# DDR0_CTLPHY_WRAP_PHY_CFG register map
Vendor: Texas Instruments
Registers are 32-bit, access per field, reset 0x0 unless marked. A register's access mark holds for its fields unless they carry their own. Offsets are as the file gives them; [hi:lo] are bit positions; lines under a group give offsets from that group; {n}, {i} and the like mark numbered series.

## DDR0_CTLPHY_WRAP_PHY_CFG (part 2 of 4)
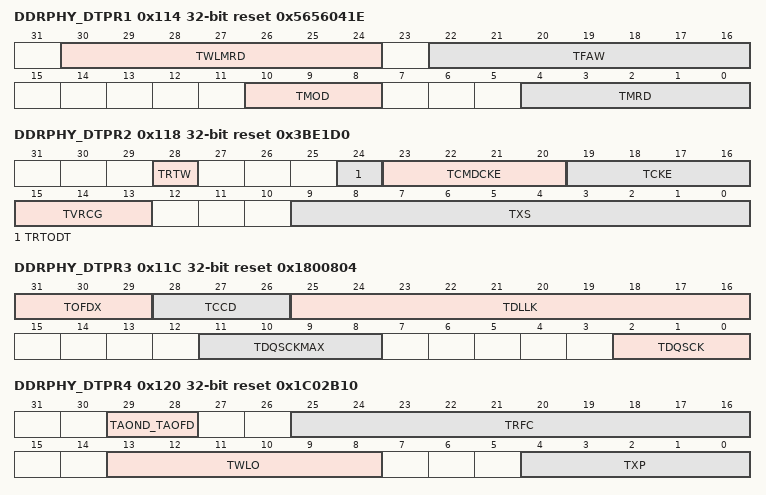
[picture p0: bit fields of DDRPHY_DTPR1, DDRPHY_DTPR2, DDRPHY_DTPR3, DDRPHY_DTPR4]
0x114 DDRPHY_DTPR1 reset 0x5656041E — DRAM Timing Parameters Register 1
  [30:24] TWLMRD rw — Minimum delay from when write leveling mode is programmed to the first DQS/DQS# rising edge. Larger values give more conservative command-to-command timings.
  [22:16] TFAW rw — 4-bank activate period. No more than 4-bank activate commands may be issued in a given tFAW period. Only applies to 8-bank devices. Valid values are 2 to 127. Larger values give more conservative command-to-command timings.
  [10:8] TMOD rw — Load mode update delay (DDR4 and DDR3 only). The minimum time between a load mode register command and a non-load mode register command. Valid values for DDR4 are:
  [4:0] TMRD rw — Load mode cycle time: The minimum time between a load mode register command and any other command. For DDR3 this is the minimum time between two load mode register commands. An offset is applied in some DRAM modes to extend the range of the register as follows:
0x118 DDRPHY_DTPR2 reset 0x3BE1D0 — DRAM Timing Parameters Register 2
  [28] TRTW rw — Read to Write command delay. Valid values are:
  [24] TRTODT rw — Read to ODT delay. Setting to 1 increases read-to-write transaction spacing by 1 DRAM clock cycle. This is intended a programmable margin for host ODT turn-off timing.
  [23:20] TCMDCKE rw — LPDDR4 mode only. tCMDCKE - Delay from Valid command to CKE Input low. Also used for tESCKE - Delay from SRE command to CKE Input low
  [19:16] TCKE rw — CKE minimum pulse width. Also specifies the minimum time that the SDRAM must remain in power down or self refresh mode. For DDR3 and LPDDR3, this parameter must be set to the value of tCKESR which is usually bigger than the value of tCKE. Valid values are 2 to 15. Larger values give more conservative command-to-command timings.
  [15:13] TVRCG rw — tVRCG_ENABLE/VRCG_DISABLE - VREF high current mode enable/Disable time for MR13 MRW during DRAM initialization in LPDDR4 mode. Number of DRAM clocks required to meet tVRCG_ENABLE/VRCG_DISABLE timing. Valid values are:
  [9:0] TXS rw — Self refresh exit delay. The minimum time between a self refresh exit command and any other command. This parameter must be set to the maximum of the various minimum self refresh exit delay parameters specified in the SDRAM datasheet, i.e. max(tXS, tXSDLL) for DDR3 and DDR4. Valid values are 2 to 1023. For LPDDR3 and LPDDR4 mode, program this value to set tXSR as specified in the SDRAM datasheet. Larger values give more conservative command-to-command timings.
0x11C DDRPHY_DTPR3 reset 0x1800804 — DRAM Timing Parameters Register 3
  [31:29] TOFDX rw — ODT turn-off delay extension. The delays are in clock cycles. Valid values are:
  [28:26] TCCD rw — Read to read and write to write command delay. In DDR4 mode, this field is ignored and MR6.tCCDL is used instead. Valid values are:
  [25:16] TDLLK rw — DLL locking time. The PUB adds an offset of 128 to this programmed register value to derive the final tDLLK value. Valid values are 0 to 1023, giving valid tDLLK values of 128 to 1151. Default value gives tDLLK value of 512.
  [11:8] TDQSCKMAX rw — Maximum DQS output access time from CK/CK# (LPDDR3/4 only). This value is used for implementing read-to-write spacing. Valid values are 1 to 8. Programming larger values increase read-to-write timing margins; smaller value optimize read-to-write scheduling (provided protocol requirements are still met).
  [2:0] TDQSCK rw — DQS output access time from CK/CK# (LPDDR3/4 only). This value is used for computing the read latency. Valid values are 1 to 8.
0x120 DDRPHY_DTPR4 reset 0x1C02B10 — DRAM Timing Parameters Register 4
  [29:28] TAOND_TAOFD rw — ODT turn-on/turn-off delays. The delays are in clock cycles. Valid values are:
  [25:16] TRFC rw — Refresh-to-Refresh: Indicates the minimum time, in clock cycles, between two refresh commands or between a refresh and an active command. This is derived from the minimum refresh interval from the datasheet, tRFC(min), divided by the clock cycle time. The default number of clock cycles is for the largest JEDEC tRFC(min parameter value supported. Larger values give more conservative command-to-command timings.
  [13:8] TWLO rw — Write leveling output delay: Number of clock cycles from when write leveling DQS is driven high by the control block to when the results from the SDRAM on DQ is sampled by the control block. This must include the SDRAM tWLO timing parameter plus the round trip delay from control block to SDRAM back to control block. Larger values give more conservative command-to-command timings.
  [4:0] TXP rw — Power down exit delay
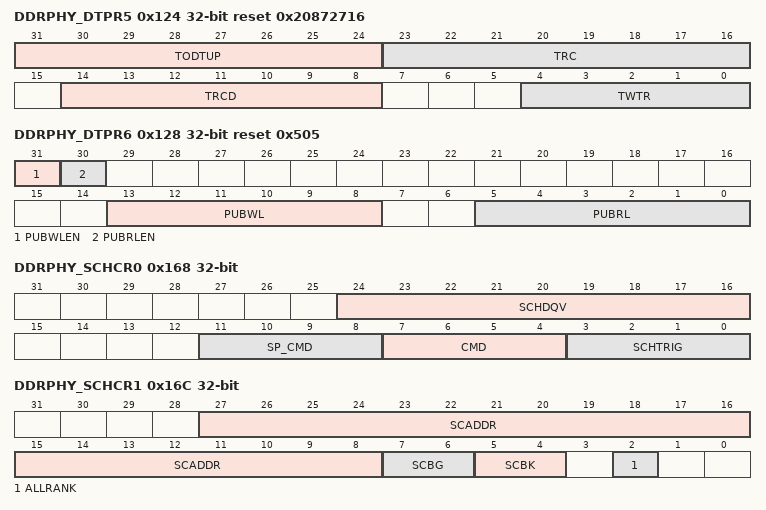
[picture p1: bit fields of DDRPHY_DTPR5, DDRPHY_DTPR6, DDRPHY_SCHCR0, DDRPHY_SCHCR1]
0x124 DDRPHY_DTPR5 reset 0x20872716 — DRAM Timing Parameters Register 5
  [31:24] TODTUP rw — LPDDR4 CA ODT value update time in DRAM clocks. This timing parameter is used during MRW to MR11 during PUB DRAM initialization. The default value of 32 DRAM clocks is to meet timing requirement of 20ns at 3200Mbps speed. Larger values give more conservative command-to-command timings.
  [23:16] TRC rw — Activate to activate command delay (same bank).
  [14:8] TRCD rw — Activate to read or write delay. Minimum time from when an activate command is issued to when a read or write to the activated row can be issued. In LPDDR3 mode, use tRCD(slow) - max(24ns,3nCK) to set this parameter. Also PUB adds an offset of 8 to the register value. In DDR3, DDR4, and LPDDR4 modes, no offset is added. Larger values give more conservative command-to-command timings.
  [4:0] TWTR rw — DRAM Internal write to read command delay. For DDR4, use tWTR_L (write-to-read delay for same bank group). Larger values give more conservative command-to-command timings.
0x128 DDRPHY_DTPR6 reset 0x505 — DRAM Timing Parameters Register 6
  [31] PUBWLEN rw — PUB Write Latency Enable: Specifies, if set, that the PUB should use the write latency specified in DDRPHY_DTPR6[PUBWL]. Otherwise, if not set, the PUB write latency is automatically calculated from the mode register settings.
  [30] PUBRLEN rw — PUB Read Latency Enable: Specifies, if set, that the PUB should use the read latency specified in DDRPHY_DTPR6[PUBRL]. Otherwise, if not set, the PUB read latency is automatically calculated from the mode register settings.
  [13:8] PUBWL rw — Write Latency: Specifies the write latency that should be used inside the PUB when DDRPHY_DTPR6[PUBWL] is set to 1. Valid values are 1 to 31. If PUBWLEN is not set, then the PUB write latency is automatically calculated from the mode register settings.
  [5:0] PUBRL rw — Read Latency: Specifies the read latency that should be used inside the PUB when DDRPHY_DTPR6[PUBRLEN] is set to 1. Valid values are 1 to 31. If PUBRL is not set, then the PUB read latency is automatically calculated from the mode register settings.
0x168 DDRPHY_SCHCR0 access not given — Scheduler Command Register 0
  [24:16] SCHDQV rw — Scheduler Command DQ Value. Specifies the value to be driven on the DQ bus during a mode register set command in per-DRAM addressability mode (DDR4 only). Each bit specifies a value to be driven on all DQ bits for a lane. Bit [0] is for the DQ bits on lane 0, bit [1] is for the DQ bits on lane 1, etc.
  [11:8] SP_CMD rw — Special Command codes: Only applicable when CMD field is set to SPECIAL_COMMAND(4’b0111) Valid values are:
  [7:4] CMD rw — Specifies the Command to be issued. Valid values are:
  [3:0] SCHTRIG — Mode Register Command Trigger: Initialization Trigger: A write of ‘1’ to this bit triggers the mode register command FSM to issue commands specified in bits [11:2] of this register. A bit setting of 1 means the step will be executed as part of the sequence, while a setting of ‘0’ means the step will be bypassed. The Mod Register Set trigger bit is self-clearing. (access RW1C)
0x16C DDRPHY_SCHCR1 — Scheduler Command Register 1
  [27:8] SCADDR rw — Scheduler Command Address Specifies the value to be driven on the address bus.
  [7:6] SCBG rw — Scheduler Command Bank Group: Specifies the value to be driven on BG[1:0] .
  [5:4] SCBK rw — Scheduler Command Bank Address: Specifies the value to be driven on BA[1:0] .
  [2] ALLRANK rw — All Ranks enabled: When set the commands issued by the mode register command FSM are set to all ranks.
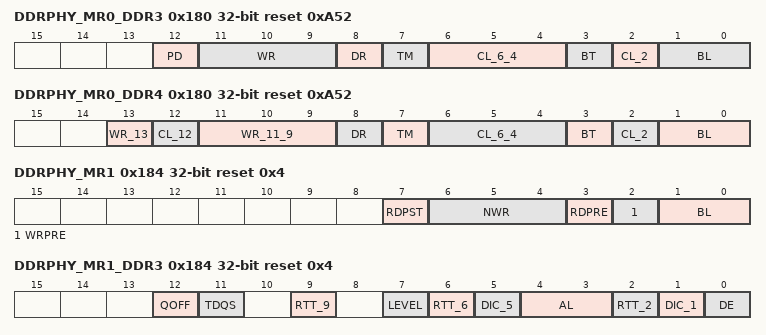
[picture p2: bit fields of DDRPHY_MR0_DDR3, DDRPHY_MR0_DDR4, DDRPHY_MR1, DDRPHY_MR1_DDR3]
0x180 DDRPHY_MR0_DDR3 reset 0xA52 — DDR3 Mode Register 0
  [12] PD rw — Power-Down Control: Controls the exit time for power-down modes. Refer to SDRAM datasheet for details on power-down modes. Valid values are:
  [11:9] WR rw — Write Recovery: This is the value of the write recovery in clock cycles. It is calculated by dividing the datasheet write recovery time, tWR (ns) by the datasheet clock cycle time, tCK (ns) and rounding up a non-integer value to the next integer. Valid values are:
  [8] DR rw — DLL Reset: Writing a 1b1 to this bit will reset the SDRAM DLL. The recommendation is to program this bit to 1b0 at all times.
  [7] TM rw — Operating Mode: Selects either normal operating mode (0) or test mode (1). Test mode is RESERVED for the manufacturer and should not be used.
  [6:4] CL_6_4 rw — CAS Latency: The delay, in clock cycles, between when the SDRAM registers receive a read command to when data is available. Valid values are:
  [3] BT rw — Burst Type: Indicates whether a burst is sequential (0) or interleaved (1).
  [2] CL_2 rw — CAS Latency: The delay, in clock cycles, between when the SDRAM registers receive a read command to when data is available. Valid values are:
  [1:0] BL rw — Burst Length: Determines the maximum number of column locations that can be accessed during a given read or write command. Valid values are:
0x180 DDRPHY_MR0_DDR4 reset 0xA52 — DDR4 Mode Register 0
  [13] WR_13 rw — Write Recovery and Read to Precharge
  [12] CL_12 rw — CAS Latency: The delay, in clock cycles, between when the SDRAM registers a read command to when data is available. Valid values are:
  [11:9] WR_11_9 rw — Write Recovery and Read to Precharge: Write Recovery and Read to Precharge. Valid values are:
  [8] DR rw — DLL Reset: Writing a 1b1 to this bit will reset the SDRAM DLL. The recommendation is to program this bit to 1b0 at all times.
  [7] TM rw — Operating Mode: Selects either normal operating mode (0) or test mode (1). Test mode is RESERVED for the manufacturer and should not be used.
  [6:4] CL_6_4 rw — CAS Latency: The delay, in clock cycles, between when the SDRAM registers receive a read command to when data is available. Valid values are:
  [3] BT rw — Burst Type: Indicates whether a burst is sequential (0) or interleaved (1).
  [2] CL_2 rw — CAS Latency: The delay, in clock cycles, between when the SDRAM registers receive a read command to when data is available. Valid values are:
  [1:0] BL rw — Burst Length: Determines the maximum number of column locations that can be accessed during a given read or write command. Valid values are:
0x184 DDRPHY_MR1 reset 0x4 — LPDDR4 Mode Register 1
  [7] RDPST rw — Read Postamble Length
  [6:4] NWR rw — Write-recovery for auto-precharge command
  [3] RDPRE rw — Read Preamble Type
  [2] WRPRE rw — Write Preamble length
  [1:0] BL rw — Burst length:
0x184 DDRPHY_MR1_DDR3 reset 0x4 — DDR3 Mode Register 1
  [12] QOFF rw — Output Enable/Disable: When 1b0, all outputs function normal; when 1b1 all SDRAM outputs are disabled removing output buffer current. This feature is intended to be used for IDD characterization of read current and should not be used in normal operation.
  [11] TDQS rw — Termination Data Strobe: When enabled (1b1) TDQS provides additional termination resistance outputs that may be useful in some system configurations. Refer to the SDRAM datasheet for details.
  [9] RTT_9 rw — On Die Termination: Selects the effective resistance for SDRAM on die termination. Valid values are:
  [7] LEVEL rw — Write Leveling Enable: Enables write-leveling when set.
  [6] RTT_6 rw — On Die Termination: Selects the effective resistance for SDRAM on die termination. Valid values are:
  [5] DIC_5 rw — Output Driver Impedance Control: Controls the output drive strength. Valid values are:
  [4:3] AL rw — Posted CAS Additive Latency: Setting additive latency that allows read and write commands to be issued to the SDRAM earlier than normal (refer to SDRAM datasheet for details). Valid values are:
  [2] RTT_2 rw — On Die Termination: Selects the effective resistance for SDRAM on die termination. Valid values are:
  [1] DIC_1 rw — Output Driver Impedance Control: Controls the output drive strength. Valid values are:
  [0] DE rw — DLL Enable/Disable
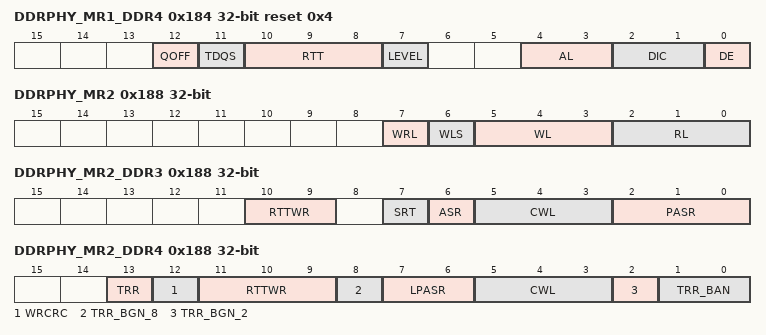
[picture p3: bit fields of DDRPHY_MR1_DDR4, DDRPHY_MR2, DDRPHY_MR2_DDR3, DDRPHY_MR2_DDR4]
0x184 DDRPHY_MR1_DDR4 reset 0x4 — DDR4 Mode Register 1
  [12] QOFF rw — Output Enable/Disable: When ‘0’, all outputs function normal; when ‘1’ all SDRAM outputs are disabled removing output buffer current. This feature is intended to be used for IDD characterization of read current and should not be used in normal operation.
  [11] TDQS rw — Termination Data Strobe: When enabled (‘1’) TDQS provides additional termination resistance outputs that may be useful in some system configurations. Refer to the SDRAM datasheet for details.
  [10:8] RTT rw — On Die Termination: Selects the effective resistance for SDRAM on die termination. Valid values are:
  [7] LEVEL rw — Write Leveling Enable: Enables write-leveling when set.
  [4:3] AL rw — Posted CAS Additive Latency: Setting additive latency that allows read and write commands to be issued to the SDRAM earlier than normal (refer to SDRAM datasheet for details). Valid values are:
  [2:1] DIC rw — Output Driver Impedance Control: Controls the output drive strength. Valid values are:
  [0] DE rw — DLL Enable/Disable
0x188 DDRPHY_MR2 — LPDDR4 Mode Register 2
  [7] WRL rw — Write Leveling
  [6] WLS rw — Write Latency Set
  [5:3] WL rw — WL Set A (MR2 OP[6] = 0b)
  [2:0] RL rw — RL and nRTP for DBI-RD Disabled (MR3 OP[6] =0b)
0x188 DDRPHY_MR2_DDR3 — DDR3 Mode Register 2
  [10:9] RTTWR rw — Dynamic ODT: Selects RTT for dynamic ODT. Valid values are:
  [7] SRT rw — Self-Refresh Temperature Range: Selects either normal (‘0’) or extended (‘1’) operating temperature range during self-refresh.
  [6] ASR rw — Auto Self-Refresh: When enabled (‘1’), SDRAM automatically provides self-refresh power management functions for all supported operating temperature values. Otherwise the SRT bit must be programmed to indicate the temperature range.
  [5:3] CWL rw — CAS Write Latency: The delay, in clock cycles, between when the SDRAM registers receive a write command to when write data is available. Valid values are:
  [2:0] PASR rw — Partial Array Self Refresh: Specifies that data located in areas of the array beyond the specified location will be lost if self refresh is entered. Valid settings for 4 banks are:
0x188 DDRPHY_MR2_DDR4 — DDR4 Mode Register 2
  [13] TRR rw — TRR Mode setting:
  [12] WRCRC rw — Write CRC. When ‘`1’, CRC is enabled for write operation.
  [11:9] RTTWR rw — Dynamic ODT: Selects RTT for dynamic ODT. Valid values are:
  [8] TRR_BGN_8 rw — Defines the bank group (BGn) to which TRR will be applied
  [7:6] LPASR rw — Low Power Array Self Refresh (LP ASR). Valid values are:
  [5:3] CWL rw — CAS Write Latency: The delay, in clock cycles, between when the SDRAM registers a write command to when write data is available. Valid values are:
  [2] TRR_BGN_2 rw — Defines the bank group (BGn) to which TRR will be applied
  [1:0] TRR_BAN rw — Defines which bank (BAn) the target row is located.
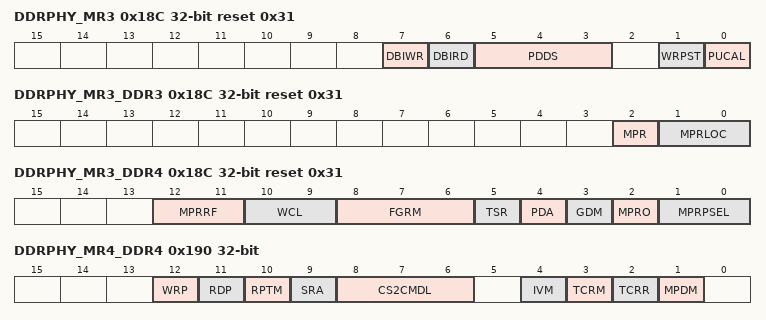
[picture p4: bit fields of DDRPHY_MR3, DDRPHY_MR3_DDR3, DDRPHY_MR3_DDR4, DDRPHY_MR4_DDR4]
0x18C DDRPHY_MR3 reset 0x31 — LPDDR4 Mode Register 3
  [7] DBIWR rw — DBI-write enable
  [6] DBIRD rw — DBI-read enable
  [5:3] PDDS rw — Pull-down drive strength
  [1] WRPST rw — Write Post-amble Length
  [0] PUCAL rw — Pull-up calibration point
0x18C DDRPHY_MR3_DDR3 reset 0x31 — DDR3 Mode Register 3
  [2] MPR rw — Multi-Purpose Register Enable: Enables, if set, that read data should come from the Multi-Purpose Register. Otherwise read data come from the DRAM array.
  [1:0] MPRLOC rw — Multi-Purpose Register (MPR) Location: Selects MPR data location: Valid value are:
0x18C DDRPHY_MR3_DDR4 reset 0x31 — DDR4 Mode Register 3
  [12:11] MPRRF rw — Multi-Purpose Register Read Format Valid values are:
  [10:9] WCL rw — Write Command Latency when CRC and DM are enabled. Valid values are:
  [8:6] FGRM rw — Fine Granularity Refresh Mode. Valid values are:
  [5] TSR rw — Temp sensor readout
  [4] PDA rw — Per DRAM Addressability: Enables, when set, per DRAM addressability to select a device on a rank.
  [3] GDM rw — Geardown Mode: Specifies the internal clocking rate used for geardown mode:
  [2] MPRO rw — Multi-Purpose Operation: Enables, if set, normal MPR operation. Otherwise MPR operation is to write or read data to/from the MPR.
  [1:0] MPRPSEL rw — Multi-Purpose Register (MPR) Page Selection: Selects MPR data location: Valid value are:
{0x180+4i} DDRPHY_MR{i} (i=4..7) — LPDDR4 Mode Register {i}
0x190 DDRPHY_MR4_DDR3 — DDR3 Mode Register 4
0x190 DDRPHY_MR4_DDR4 — DDR4 Mode Register 4
  [12] WRP rw — Write Preamble. Valid values are:
  [11] RDP rw — Read Preamble
  [10] RPTM rw — Read Preamble Training Mode
  [9] SRA rw — Self Refresh Abord
  [8:6] CS2CMDL rw — CS to Command Latency Mode Valid values are:
  [4] IVM rw — Internal Vref Monitor:
  [3] TCRM rw — Temperature Controlled Refresh Mode
  [2] TCRR rw — Temperature Controlled Refresh Range
  [1] MPDM rw — Maximum Power Down Mode
0x194 DDRPHY_MR5_DDR3 reset 0x400 — DDR3 Mode Register 5
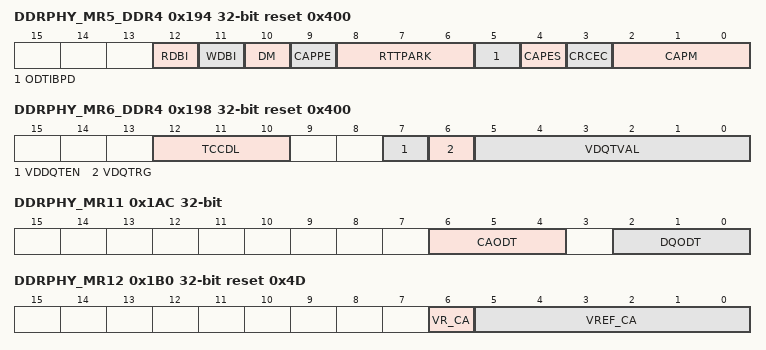
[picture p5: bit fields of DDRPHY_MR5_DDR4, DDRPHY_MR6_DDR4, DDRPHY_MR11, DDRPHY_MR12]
0x194 DDRPHY_MR5_DDR4 reset 0x400 — DDR4 Mode Register 5
  [12] RDBI rw — Read DBI
  [11] WDBI rw — Write DBI
  [10] DM rw — Data Mask
  [9] CAPPE rw — CA parity Persistent Error
  [8:6] RTTPARK rw — RTT_PARK Valid values are:
  [5] ODTIBPD rw — ODT Input Buffer during Power Down mode
  [4] CAPES rw — C/A Parity Error Status
  [3] CRCEC rw — CRC Error Clear
  [2:0] CAPM rw — C/A Parity Latency Mode Valid values are:
0x198 DDRPHY_MR6_DDR3 reset 0x400 — DDR3 Mode Register 6
0x198 DDRPHY_MR6_DDR4 reset 0x400 — DDR4 Mode Register 6
  [12:10] TCCDL rw — CAS_n to CAS_n command delay for same bank group (tCCD_L). Valid values are:
  [7] VDDQTEN rw — VrefDQ Training Enable
  [6] VDQTRG rw — VrefDQ Training Range
  [5:0] VDQTVAL rw — VrefDQ Training Values Refer to the JEDEC spec for more information
0x19C DDRPHY_MR7_DDR3 — LPDDR2 Mode Register 7
0x19C DDRPHY_MR7_DDR4 — DDR4 Mode Register 7
  [15:0] RSVD_15_0 rw — Reserve for future use.
0x1AC DDRPHY_MR11 — LPDDR4 Mode Register 11
  [6:4] CAODT rw, [2:0] DQODT rw
0x1AC DDRPHY_MR11_DDR3 — DDR3 Mode Register 11
0x1AC DDRPHY_MR11_DDR4 — DDR4 Mode Register 11
0x1B0 DDRPHY_MR12 reset 0x4D — LPDDR4 Mode Register 12
  [6] VR_CA rw — VREF DQ Range select 0b: Range[0] enabled 1b: Range[1] enabled
  [5:0] VREF_CA rw — Controls the VREF(ca) levels for Frequency-Set-Point[1:0]. Values from either VR(ca)[0] or VR(ca)[1] may be selected by setting VR-CA appropriately.
0x1B0 DDRPHY_MR12_DDR3 reset 0x4D — DDR3 Mode Register 12
0x1B0 DDRPHY_MR12_DDR4 reset 0x4D — DDR4 Mode Register 12
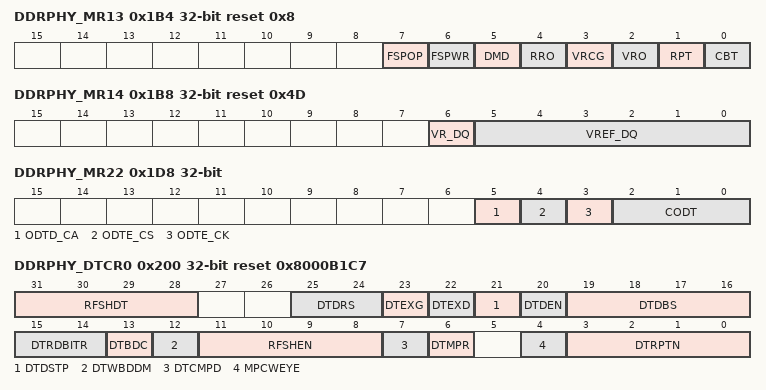
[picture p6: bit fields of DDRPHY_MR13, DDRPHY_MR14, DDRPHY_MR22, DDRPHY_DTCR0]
0x1B4 DDRPHY_MR13 reset 0x8 — LPDDR4 Mode Register 13
  [7] FSPOP rw — Frequency Set Point Operation mode
  [6] FSPWR rw — Frequency Set Point Write enable
  [5] DMD rw — Data mask disable:
  [4] RRO rw — Refresh Rate Option
  [3] VRCG rw — Vref current generator:
  [2] VRO rw — Vref Output:
  [1] RPT rw — Read Preamble Training Mode
  [0] CBT rw — Command Bus Training:
0x1B4 DDRPHY_MR13_DDR3 reset 0x8 — DDR3 Mode Register 13
0x1B4 DDRPHY_MR13_DDR4 reset 0x8 — DDR4 Mode Register 13
0x1B8 DDRPHY_MR14 reset 0x4D — LPDDR4 Mode Register 14
  [6] VR_DQ rw — VREF DQ Range select 0b: Range[0] enabled 1b: Range[1] enabled
  [5:0] VREF_DQ rw — Controls the VREF(dq) levels for Frequency-Set-Point[1:0]. Values from either VR(dq)[0] or VR(dq)[1] may be selected by setting VR_DQ appropriately.
0x1B8 DDRPHY_MR14_DDR3 reset 0x4D — DDR3 Mode Register 14
0x1B8 DDRPHY_MR14_DDR4 reset 0x4D — DDR4 Mode Register 14
0x1D8 DDRPHY_MR22 — LPDDR4 Mode Register 22
  [5] ODTD_CA rw — CA ODT termination disable
  [4] ODTE_CS rw — ODT CS override
  [3] ODTE_CK rw — ODT CK override
  [2:0] CODT rw — Host ODT value for DRAM Voh calibration
0x1D8 DDRPHY_MR22_DDR3 — DDR3 Mode Register 22
0x1D8 DDRPHY_MR22_DDR4 — DDR4 Mode Register 22
0x200 DDRPHY_DTCR0 access not given reset 0x8000B1C7 — Data Training Configuration Register 0
  [31:28] RFSHDT rw — Refresh During Training: A non-zero value specifies that a burst of refreshes equal to the number specified in this field inserted during training. Refer to the registers DDRPHY_PGCR2[TREFPRD] to define the refresh period. Programming with value of 0 in this register field will not insert any Refresh during training.
  [25:24] DTDRS rw — Data Training Debug Rank Select: Selects the rank during training debug mode.
  [23] DTEXG rw — Data Training with Early/Extended Gate: Specifies if set that the DQS gate training should be performed with an early/extended gate as specified in DDRPHY_DX8SLnDQSCTL[DQSGX]. DTEXG=1 is not supported.
  [22] DTEXD rw — Data Training Extended Write DQS: Enables, if set, an extended write DQS whereby two additional pulses of DQS are added as post-amble to a burst of writes. Generally this should only be enabled when running read bit deskew with the intention of performing read eye deskew prior to running write leveling adjustment.
  [21] DTDSTP — Data Training Debug Step: A write of ‘1’ to this bit steps the data training algorithm through a single step. This bit is self clearing. (access RW1C)
  [20] DTDEN rw — Data Training Debug Enable: Enables, if set, the data training to run in a single-step debug mode. In this mode, DTDSTP must be repeatedly asserted to step through the data training.
  [19:16] DTDBS rw — Data Training Debug Byte Select: Selects the byte during data training debug mode.
  [15:14] DTRDBITR rw — Data Training read DBI deskewing configuration. Configures the data training read bit deskewing algorithm optional RDBI deskew functionality. Valid values are:
  [13] DTBDC rw — Data Training Bit Deskew Centering: Enables, if set, eye centering capability during write and read bit deskew training.
  [12] DTWBDDM rw — Data Training Write Bit Deskew Data Mask. If set it enables write bit deskew of the data mask.
  [11:8] RFSHEN rw — Refreshes Issued During Entry to Training:
  [7] DTCMPD rw — Data Training Compare Data: Specifies, if set, that DQS gate training should also check if the returning read data is correct. Otherwise data-training only checks if the correct number of DQS edges were returned.
  [6] DTMPR rw — Data Training Using MPR: Specifies, if set, that DQS gate training should use the SDRAM Multi-Purpose Register (MPR) register. Otherwise data-training is performed by first writing to some locations in the SDRAM and then reading them back.
  [4] MPCWEYE rw — WEYE Training using MPC FIFO Commands: This is applicable in LPDDR4 mode. When this bit is set to 1, WEYE training will be performed with MPC FIFO commands instead of normal Writes/Reads
  [3:0] DTRPTN rw — Data Training Repeat Number: Repeat number used to confirm stability of DDR write or read. The valid values are 1 to 15.
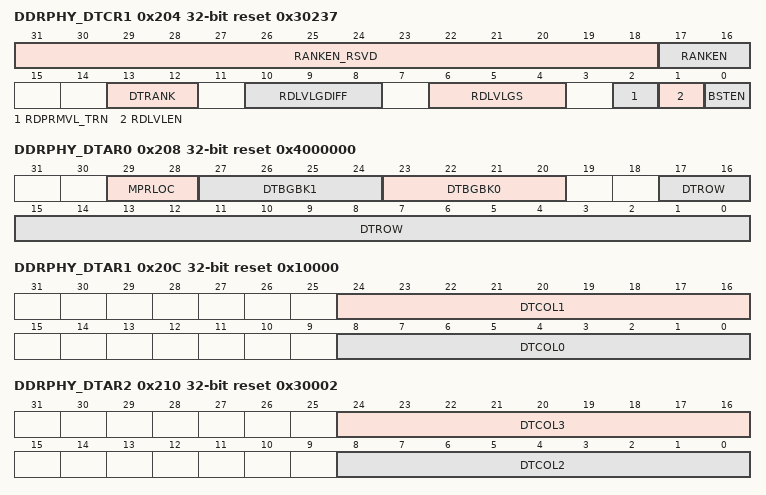
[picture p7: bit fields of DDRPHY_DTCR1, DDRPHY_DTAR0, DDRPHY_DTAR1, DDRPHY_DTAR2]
0x204 DDRPHY_DTCR1 reset 0x30237 — Data Training Configuration Register 1
  [31:18] RANKEN_RSVD ro — Reserved
  [17:16] RANKEN rw — Rank Enable.
  [13:12] DTRANK rw — Data Training Rank: Selects the SDRAM rank to be used during data bit deskew.
  [10:8] RDLVLGDIFF rw — Read Leveling Gate Sampling Difference: width of DQS sampling window. Encoded as a fraction of the DDR clock period follows:
  [6:4] RDLVLGS rw — Read Leveling Gate Shift: delay reduction to apply to gate after it has been aligned to DQS. Encoded as a fraction of the DDR clock period follows:
  [2] RDPRMVL_TRN rw — Read Preamble Training enable: engages read preamble training mode in DDR4 DRAM during gate training
  [1] RDLVLEN rw — Read Leveling Enable: Run a DQS sampling scheme using the gate to align the rising edges of DQS and the gate after which a delay reduction is applied to the gate (see RDLVLGS).
  [0] BSTEN rw — Basic Gate Training Enable: Runs a trial and error algorithm to progressively evaluate gate positions and narrow down to a working one
0x208 DDRPHY_DTAR0 reset 0x4000000 — Data Training Address Register 0
  [29:28] MPRLOC rw — Multi-Purpose Register (MPR) Location: Selects MPR data location to use as a training pattern during gate training. Valid values are:
  [27:24] DTBGBK1 rw — Data Training Bank Group and Bank Address: Selects the SDRAM bank group and bank address to be used during data training in DDR4 and LPDDR4 modes only. When in DDR4 mode, DTBGBK1[27:27] specifies the bank group and DTBGBK1[25:24] specifies the bank address. When not in DDR4 mode, DTBGBK1 is not applicable.
  [23:20] DTBGBK0 rw — Data Training Bank Group and Bank Address: Selects the SDRAM bank group and bank address to be used during data training. When in DDR4 mode, DTBGBK0[23:22] specifies the bank group and DTBGBK0[21:20] specifies the bank address. When not in DDR4 or LPDDR4 modes DTBGBK0[22:20] specify the bank address.
  [17:0] DTROW rw — Data Training Row Address: Selects the SDRAM row address to be used during data training.
0x20C DDRPHY_DTAR1 reset 0x10000 — Data Training Address Register 1
  [24:16] DTCOL1 rw — Data Training Column Address: Selects the SDRAM column address to be used during data training. Specified in multiples of 8 such that the address used is {DTCOL1,3’b000}. For LPDDR4, specified in multiples of 16 such that the address used is (DTCOLn,4'b0000).
  [8:0] DTCOL0 rw — Data Training Column Address: Selects the SDRAM column address to be used during data training. Specified in multiples of 8 such that the address used is {DTCOL0,3’b000}. For LPDDR4, specified in multiples of 16 such that the address used is (DTCOLn,4'b0000).
0x210 DDRPHY_DTAR2 reset 0x30002 — Data Training Address Register 2
  [24:16] DTCOL3 rw — Data Training Column Address: Selects the SDRAM column address to be used during data training. Specified in multiples of 8 such that the address used is {DTCOL3,3’b000}. For LPDDR4, specified in multiples of 16 such that the address used is (DTCOLn,4'b0000).
  [8:0] DTCOL2 rw — Data Training Column Address: Selects the SDRAM column address to be used during data training. Specified in multiples of 8 such that the address used is {DTCOL2,3’b000}. For LPDDR4, specified in multiples of 16 such that the address used is (DTCOLn,4'b0000).
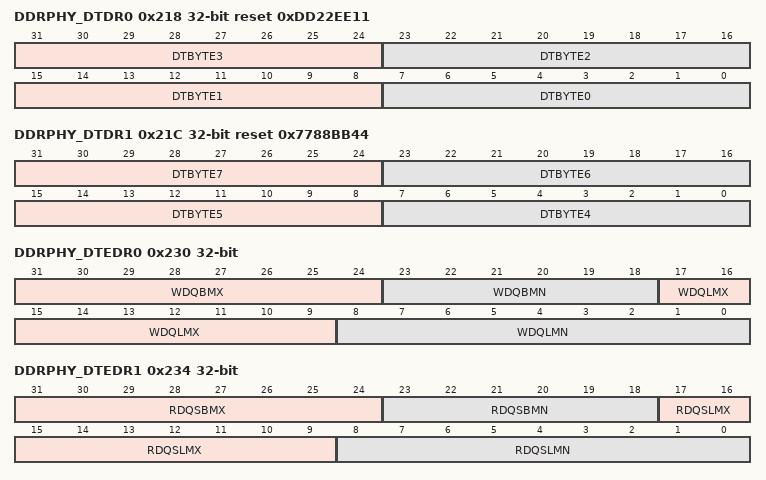
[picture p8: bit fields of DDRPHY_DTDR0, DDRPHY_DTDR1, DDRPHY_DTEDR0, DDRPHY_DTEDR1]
0x218 DDRPHY_DTDR0 rw reset 0xDD22EE11 — Data Training Data Register 0
  [31:24] DTBYTE3 — Data Training Data: The fourth beat of data used during non-MPRbased QS gate training (basic algorithm). This same data byte is used for each Byte Lane.
  [23:16] DTBYTE2 — Data Training Data: The third beat of data used during non-MPRbased QS gate training (basic algorithm). This same data byte is used for each Byte Lane.
  [15:8] DTBYTE1 — Data Training Data: The second beat of data used during non-MPRbased QS gate training (basic algorithm). This same data byte is used for each Byte Lane.
  [7:0] DTBYTE0 — Data Training Data: The first beat of data used during non-MPRbased QS gate training (basic algorithm). This same data byte is used for each Byte Lane.
0x21C DDRPHY_DTDR1 rw reset 0x7788BB44 — Data Training Data Register 1
  [31:24] DTBYTE7 — Data Training Data: The eighth beat of data used during non-MPRbased QS gate training (basic algorithm). This same data byte is used for each Byte Lane.
  [23:16] DTBYTE6 — Data Training Data: The seventh beat of data used during non-MPRbased QS gate training (basic algorithm). This same data byte is used for each Byte Lane.
  [15:8] DTBYTE5 — Data Training Data: The sixth beat of data used during non-MPR-based QS gate training (basic algorithm). This same data byte is used for each Byte Lane.
  [7:0] DTBYTE4 — Data Training Data: The fifth beat of data used during non-MPR-based QS gate training (basic algorithm). This same data byte is used for each Byte Lane.
0x230 DDRPHY_DTEDR0 ro — Data Training Eye Data Register 0
  [31:24] WDQBMX — This field is the delay that is added to all write dq BDLs during write eye centering to detect the right DQ edges.
  [23:18] WDQBMN — This field is the delay that is added to all write dq BDLs during write eye centering to detect the left DQ edges.
  [17:9] WDQLMX — Data Training WDQ LCDL Maximum.
  [8:0] WDQLMN — Data Training WDQ LCDL Minimum.
0x234 DDRPHY_DTEDR1 ro — Data Training Eye Data Register 1
  [31:24] RDQSBMX — This field is the delay that is added to all read dq BDLs during read eye centering to detect the right DQ edges that are sampled by RDQS.
  [23:18] RDQSBMN — This field is the delay that is added to all read dq BDLs during read eye centering to detect the left DQ edges that are sampled by RDQS.
  [17:9] RDQSLMX — Data Training RDQS LCDL Maximum.
  [8:0] RDQSLMN — Data Training RDQS LCDL Minimum.
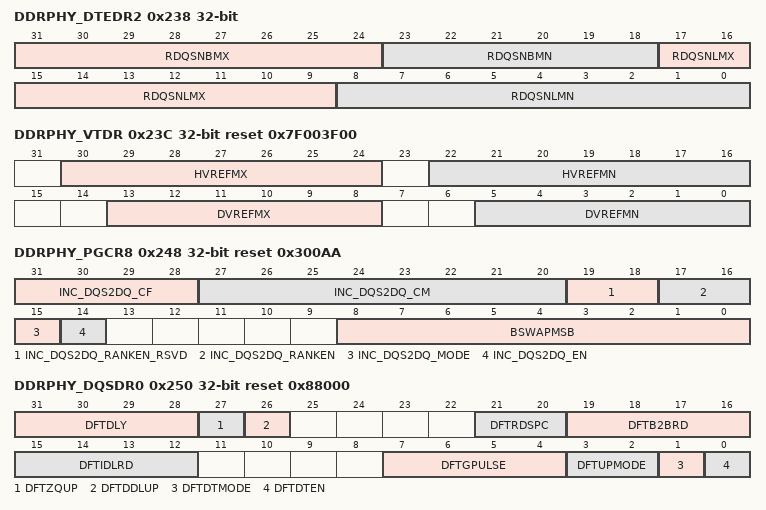
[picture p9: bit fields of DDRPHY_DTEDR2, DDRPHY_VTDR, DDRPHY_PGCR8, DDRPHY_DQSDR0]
0x238 DDRPHY_DTEDR2 ro — Data Training Eye Data Register 2
  [31:24] RDQSNBMX — This field is the delay that is added to all read dq BDLs during read eye centering to detect the left DQ edges that are sampled by RDQSN.
  [23:18] RDQSNBMN — This field is the delay that is added to all read dq BDLs during read eye centering to detect the left DQ edges that are sampled by RDQSN.
  [17:9] RDQSNLMX — Data Training RDQSN LCDL Maximum.
  [8:0] RDQSNLMN — Data Training RDQSN LCDL Minimum.
0x23C DDRPHY_VTDR ro reset 0x7F003F00 — VREF Training Data Register
  [30:24] HVREFMX — Host IOVREF Maximum.
  [22:16] HVREFMN — Host IO VREF Minimum.
  [13:8] DVREFMX — DRAM DQ VREF Maximum.
  [5:0] DVREFMN — DRAM DQ VREF Minimum.
0x248 DDRPHY_PGCR8 reset 0x300AA — PHY General Configuration Register 8
  [31:28] INC_DQS2DQ_CF rw — Counter Cycles Factor
  [27:20] INC_DQS2DQ_CM rw — Counter Cycle Multiplier
  [19:18] INC_DQS2DQ_RANKEN_RSVD ro — Rank Enable
  [17:16] INC_DQS2DQ_RANKEN rw — Rank Enable
  [15] INC_DQS2DQ_MODE rw — Self Incremental DQS2DQ Training
  [14] INC_DQS2DQ_EN rw — Incremental DQS2DQ Training: when set the DQS2DQ delay update logic is active and Incremental DQS2DQ training is performed.
  [8:0] BSWAPMSB rw — When a bit is set, it indicates that the corresponding PHY byte lane is connected to MSByte of the LPDDR4 DRAM 16 bit instance it is connected to.
0x250 DDRPHY_DQSDR0 reset 0x88000 — DQS Drift Register 0
  [31:28] DFTDLY rw — Number of delay taps by which the DQS gate LCDL will be updated when DQS drift is detected. Valid values are:
  [27] DFTZQUP rw — Drift Impedance Update: Specifies if set that the PUB should also update the I/O impedance whenever it requests and get granted the DFI bus from the controller for DQS drift updates. This feature is not supported in this revision of the PUB.
  [26] DFTDDLUP rw — Drift DDL Update: Specifies if set that the PUB should also update DDLs whenever it requests and get granted the DFI bus from the controller for DQS drift updates. This feature is not supported in this revision of the PUB.
  [21:20] DFTRDSPC rw — Drift Read Spacing. Specifies by how much the reads that are generated by the PUB for drift compensation should be spaced from each when either DDRPHY_DQSDR0[DFTIDLRD] or DDRPHY_DQSDR0[DFTB2BRD] is set to a value greater than 1. Valid values are:
  [19:16] DFTB2BRD rw — Drift Back-to-Back Reads: Specifies the number of reads that the PUB should generate when it is configured to break long continuous back-to-back reads from the controller to allow it to sense drift. This is useful if the PUB is configured not to detect drift on every cycle, i.e. when DFTGPULSE is set to 4b000.
  [15:12] DFTIDLRD rw — Drift Idle Reads: Specifies the number of reads that the PUB should generate when it is configured to issue periodic reads when there have been no reads from the controller for a programmable number of clock cycles. Valid values are 1 (specified by 4b0001) to 15 (specified by 4b1111).
  [7:4] DFTGPULSE rw — Gate Pulse Enable: Specifies the DDR clocks when the qs_gate signal is 1b0 when the gate is supposed to be open. Valid values are:
  [3:2] DFTUPMODE rw — DQS Drift Update Mode: Specifies the DQS update mode to use. Valid values are:
  [1] DFTDTMODE rw — DQS Drift Detection Mode: Specifies the DQS detection mode to use. Valid values are:
  [0] DFTDTEN rw — DQS Drift Detection Enable: Indicates when set that the DQS drift monitoring and delay update logic is active. Valid values are:
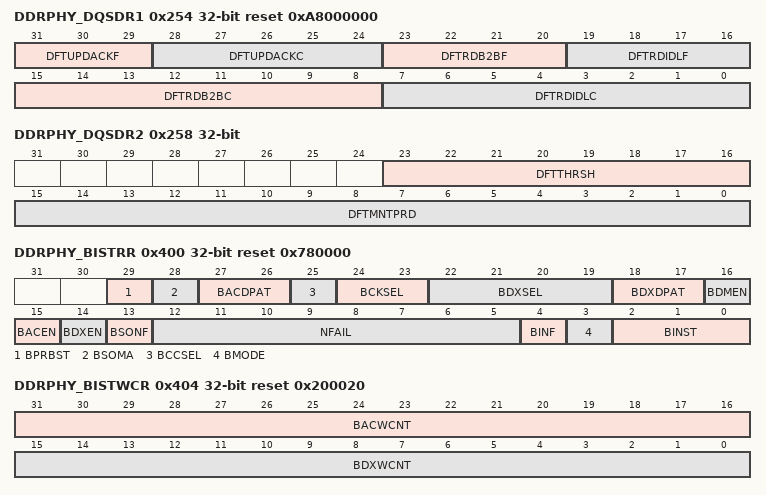
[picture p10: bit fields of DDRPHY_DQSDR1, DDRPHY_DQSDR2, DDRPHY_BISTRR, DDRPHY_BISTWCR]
0x254 DDRPHY_DQSDR1 rw reset 0xA8000000 — DQS Drift Register 1
  [31:29] DFTUPDACKF — Drift DFI Update Request ACK to DQS Drift FSM issuing IDLE Read’s Cycles Factor: Specifies the multiplication factor for the value specified in DDRPHY_DQSDR1[DFTUPDACKC]. Valid values are:
  [28:24] DFTUPDACKC — Drift DFI Update Request ACK to DQS Drift FSM issuing IDLE Read’s Cycles: Specifies the number wait of clock cycles from Drift DFI Update request ACK to Drift FSM issuing IDLE Reads . The value specified in this field is multiplied by a factor specified in DDRPHY_DQSDR1[DFTUPDACKF]. Specifying a value of 0 disables the thw wait cycles.
  [23:20] DFTRDB2BF — Drift Back-to-Back Read Cycles Factor: Specifies the multiplication factor for the value specified in DQSDR.DFTRDB2BC. Valid values are:
  [19:16] DFTRDIDLF — Drift Idle Read Cycles Factor: Specifies the multiplication factor for the value specified in DQSDR.DFTRDIDLC. Valid values are:
  [15:8] DFTRDB2BC — Drift Back-to-Back Read Cycles: Specifies the number of continuous back-to-back read clock cycles from the controller after which the PUB should interrupt the controller so that it can update drift. This is useful if the PUB is configured not to detect drift on every cycle, i.e. when DFTGPULSE is set to 4’b000. The value specified in this field is multiplied by a factor specified in DDRPHY_DQSDR1[DFTRDB2BF]. Specifying a value of 0 disables the PUB from interrupting controller back-to-back reads.
  [7:0] DFTRDIDLC — Drift Idle Read Cycles: Specifies the number of clock cycles after which the PUB should generate reads when there have been no reads from the controller. The value specified in this field is multiplied by a factor specified in DDRPHY_DQSDR1[DFTRDIDLF]. Specifying a value of 0 disables the PUB from issuing these reads.
0x258 DDRPHY_DQSDR2 — DQS Drift Register 2
  [23:16] DFTTHRSH rw — Drift Threshold: Specifies the minimum number of DQS drift detections in one direction in order to declare it as a valid DQS drift. Any drift in the opposite direction before hitting this threshold will reset the detection counter.
  [15:0] DFTMNTPRD rw — Drift Monitor Period: Specifies the minimum number of clock cycles between two drift monitor events. This field controls how often the drift status from the DATX8 is sampled by the PUB and used to compensate the drift. Note that this field only controls the minimum period of drift monitoring/compensation. The maximum period will depend on how often the reads are sent to the DRAM using either the controller or the PUB (using the DDRPHY_DQSDR0[DFTIDLRD] or DDRPHY_DQSDR0[DFTB2BRD] files). All values are valid and indicate that drift should be monitored every (DFTMNTPRD+1) CTL clocks.
0x400 DDRPHY_BISTRR reset 0x780000 — BIST Run Register
  [29] BPRBST rw — PRBS Type. Determines the type of PRBS pattern used when BDXDPAT/BACDPAT is 2’b10.
  [28] BSOMA rw — BIST Stop On Maximum Address. In infinite mode (BINF == 0x1), terminate the BIST operation once the address has incremented up to the maximum specified (BISTARn registers).
  [27:26] BACDPAT rw — BIST AC Data Pattern: Selects the data pattern used during BIST AC loopback. Valid values are:
  [25] BCCSEL rw — BIST Clock Cycle Select: Selects the clock numbers on which the AC loopback data is written into the FIFO. Data is written into the loopback FIFO every two clock cycles. Valid values are:
  [24:23] BCKSEL rw — BIST CK Select: Selects the CK that should be used to register the AC loopback signals from the I/Os. Valid values are:
  [22:19] BDXSEL rw — BIST DATX8 Select: Select the byte lane for comparison of loopback/read data. When programmed value is larger than (pNO_OF_BYTES -1) all byte lanes are compared together; otherwise a single byte lane is used for comparison. When all bytes are selected, the status of bit error counters (DDRPHY_BISTBER2, DDRPHY_BISTBER3) and fail word (DDRPHY_BISTFWR2, DDRPHY_BISTFWR1[DMWEBS]) should be ignored.
  [18:17] BDXDPAT rw — BIST DxData Pattern: Selects the data pattern used during BIST Dx.Valid values are:
  [16] BDMEN rw — BIST Data Mask Enable: Enables if set that the data mask BIST should be included in the BIST run, i.e. data pattern generated and loopback data compared - valid for loopback mode where write DBI (DDR4/LPDDR4 only) is not enabled. BIST DBI Enable: If DDR4 Write DBI is enabled (MR5[WDBI]) and DDRPHY_DX8SLnDXCTL2[WDBI] is set to 1, set BDMEN to 1 to invert data as appropriate and generate the corresponding DBI; set to 0 to drive out the original un-inverted data pattern (DBI will be driven high throughout in DDR4 and 0 in LPDDR4).
  [15] BACEN rw — BIST AC Enable: Enables the running of BIST on the address/command lane PHY.
  [14] BDXEN rw — BIST DATX8 Enable: Enables the running of BIST on the data byte lane PHYs.
  [13] BSONF rw — BIST Stop On Nth Fail: Specifies if set that the BIST should stop when an nth data word or address/command comparison error has been encountered.
  [12:5] NFAIL rw — Number of Failures: Specifies the number of failures after which the execution of commands and the capture of read data should stop if BSONF bit of this register is set. Execution of commands and the capture of read data will stop after (NFAIL+1) failures if BSONF is set.
  [4] BINF rw — BIST Infinite Run: Specifies if set that the BIST should be run indefinitely until when it is either stopped or a failure has been encountered or if BSOMA is set to 0x1 when the maximum address is reached.
  [3] BMODE rw — BIST Mode: Selects the mode in which BIST is run. Valid values are:
  [2:0] BINST rw — BIST Instruction: Selects the BIST instruction to be executed Valid values are:
0x404 DDRPHY_BISTWCR rw reset 0x200020 — BIST Word Count Register
  [31:16] BACWCNT — BIST AC Word Count: Indicates the number of words to generate during BIST.
  [15:0] BDXWCNT — BIST Word Count for DX: Indicates the number of words to generate during BIST. This must be a multiple of DRAM burst length (BL) divided by 2, e.g. for BL=8, valid values are 4, 8, 12, 16, and so on.
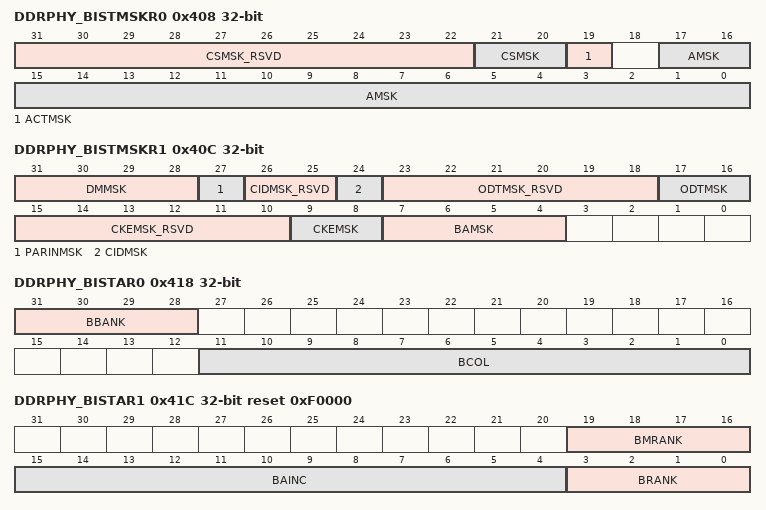
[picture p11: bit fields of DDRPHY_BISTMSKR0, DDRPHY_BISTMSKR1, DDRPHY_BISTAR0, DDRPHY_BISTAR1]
0x408 DDRPHY_BISTMSKR0 — BIST Mask Register 0
  [31:22] CSMSK_RSVD ro — Reserved.Return zeros on reads.
  [21:20] CSMSK rw — Mask bit for each of the up to 12 CS_N bits.
  [19] ACTMSK rw — Mask bit for the RAS
  [17:0] AMSK rw — Mask bit for each of the up to 16 address bits.
0x40C DDRPHY_BISTMSKR1 — BIST Mask Register 1
  [31:28] DMMSK rw — Mask bit for the data mask (DM) bit.
  [27] PARINMSK rw — Mask bit for the PAR_IN. Only for DIMM parity support.
  [26:25] CIDMSK_RSVD ro — Reserved.Return zeros on reads.
  [24] CIDMSK rw — Mask bits for each of the up to 3 Chip ID bits.
  [23:18] ODTMSK_RSVD ro — Reserved.Return zeros on reads.
  [17:16] ODTMSK rw — Mask bit for each of the up to 8 ODT bits.
  [15:10] CKEMSK_RSVD ro — Reserved.Return zeros on reads.
  [9:8] CKEMSK rw — Mask bit for each of the up to 8 CKE bits.
  [7:4] BAMSK rw — Mask bit for each of the up to 4 bank address bits.
0x410 DDRPHY_BISTMSKR2 rw — BIST Mask Register 2
  [31:0] DQMSK — DQMSK[7:0] is beat0/4 for each of the 8 DQ bits DQMSK[15:8] is beat1/5 for each of the 8 DQ bits DQMSK[23:16] is beat2/6 for each of the 8 DQ bits DQMSK[31:24] is beat3/7 for each of the 8 DQ bits
0x414 DDRPHY_BISTLSR rw reset 0x1234ABCD — BIST LFSR Seed Register
  [31:0] SEED — LFSR seed for pseudo-random BIST patterns.
0x418 DDRPHY_BISTAR0 — BIST Address Register 0
  [31:28] BBANK rw — BIST Bank Address: Selects the SDRAM bank address to be used during BIST.
  [11:0] BCOL rw — BIST Column Address: Selects the SDRAM column address to be used during BIST. The lower bits of this address must be “0000” for BL16, “000” for BL8, “00” for BL4 and “0” for BL2.
0x41C DDRPHY_BISTAR1 reset 0xF0000 — BIST Address Register 1
  [19:16] BMRANK rw — BIST Maximum Rank: Specifies the maximum SDRAM rank to be used during BIST. The default value is set to maximum ranks minus 1. Example default shown here is for a 16-rank system
  [15:4] BAINC rw — BIST Address Increment: Selects the value by which the SDRAM address is incremented for each write/read access. This value must be at the beginning of a burst boundary, i.e. the lower bits must be “0000” for BL16, “000” for BL8, “00” for BL4 and “0” for BL2.
  [3:0] BRANK rw — BIST Rank: Selects the SDRAM rank to be used during BIST. Valid values range from 0 to maximum ranks minus 1.
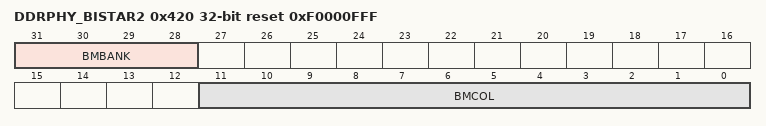
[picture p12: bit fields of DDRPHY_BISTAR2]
0x420 DDRPHY_BISTAR2 reset 0xF0000FFF — BIST Address Register 2
  [31:28] BMBANK rw — BIST Maximum Bank Address: Specifies the maximum SDRAM bank address to be used during BIST before the address increments to the next rank.
  [11:0] BMCOL rw — BIST Maximum Column Address: Specifies the maximum SDRAM column address to be used during BIST before the address increments to the next row.
0x424 DDRPHY_BISTAR3 — BIST Address Register 3
  [17:0] BROW rw — BIST Row Address: Selects the SDRAM row address to be used during BIST.
